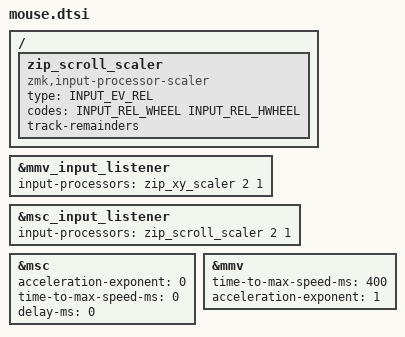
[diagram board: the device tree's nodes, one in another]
/ {
  zip_scroll_scaler: zip_scroll_scaler {
    compatible = "zmk,input-processor-scaler";
    #input-processor-cells = <2>;
    type = <INPUT_EV_REL>;
    codes = <INPUT_REL_WHEEL INPUT_REL_HWHEEL>;
    track-remainders;
  };
};

&mmv_input_listener {
       input-processors = <&zip_xy_scaler 2 1>;
};

&msc_input_listener {
       input-processors = <&zip_scroll_scaler 2 1>;
};

&msc {
    acceleration-exponent = <0>;      // 0
    time-to-max-speed-ms = <0>;       // 300
    delay-ms = <0>;                   // 0
};

&mmv {
    time-to-max-speed-ms = <400>;
    acceleration-exponent = <1>;
};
